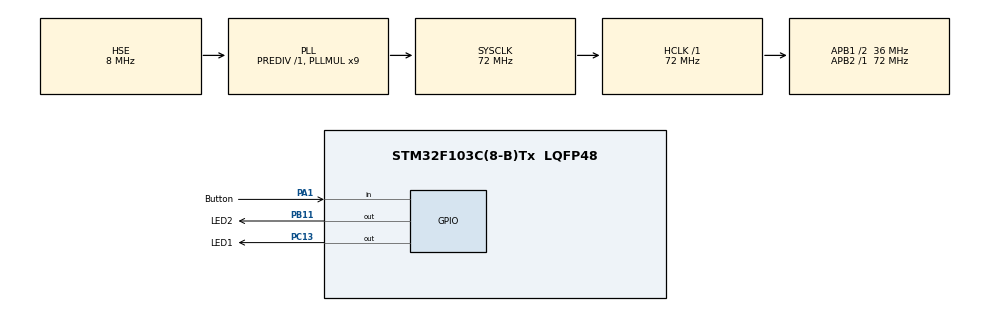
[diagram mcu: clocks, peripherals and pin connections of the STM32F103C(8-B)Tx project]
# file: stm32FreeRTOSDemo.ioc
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FREERTOS.Tasks01=task1,0,128,task1EntryFunction,Default,NULL,Dynamic,NULL,NULL;task2,-3,128,task2EntryFunction,Default,NULL,Dynamic,NULL,NULL
FREERTOS.Timers01=myTimer01,Callback01,osTimerOnce,Default,NULL,Dynamic,NULL
FREERTOS.configTIMER_TASK_PRIORITY=3
FREERTOS.configTOTAL_HEAP_SIZE=8096
FREERTOS.configUSE_TIMERS=1
Mcu.Family=STM32F1
Mcu.Name=STM32F103C(8-B)Tx
Mcu.Package=LQFP48
NVIC.PriorityGroup=NVIC_PRIORITYGROUP_4
NVIC.TIM1_UP_IRQn=true\:0\:0\:false\:false\:true\:false\:false\:true
NVIC.TimeBase=TIM1_UP_IRQn
NVIC.TimeBaseIP=TIM1
PA1.GPIO_Label=Button
PA1.Signal=GPIO_Input
PB11.GPIO_Label=LED2
PB11.Signal=GPIO_Output
PC13-TAMPER-RTC.GPIO_Label=LED1
PC13-TAMPER-RTC.Signal=GPIO_Output
PC14-OSC32_IN.Mode=LSE-External-Oscillator
PC14-OSC32_IN.Signal=RCC_OSC32_IN
PC15-OSC32_OUT.Mode=LSE-External-Oscillator
PC15-OSC32_OUT.Signal=RCC_OSC32_OUT
PD0-OSC_IN.Mode=HSE-External-Oscillator
PD0-OSC_IN.Signal=RCC_OSC_IN
PD1-OSC_OUT.Mode=HSE-External-Oscillator
PD1-OSC_OUT.Signal=RCC_OSC_OUT
ProjectManager.HeapSize=0x200
ProjectManager.StackSize=0x400
ProjectManager.TargetToolchain=Makefile
RCC.AHBFreq_Value=72000000
RCC.APB1CLKDivider=RCC_HCLK_DIV2
RCC.APB1Freq_Value=36000000
RCC.APB1TimFreq_Value=72000000
RCC.APB2Freq_Value=72000000
RCC.APB2TimFreq_Value=72000000
RCC.HCLKFreq_Value=72000000
RCC.PLLMUL=RCC_PLL_MUL9
RCC.PLLSourceVirtual=RCC_PLLSOURCE_HSE
RCC.SYSCLKFreq_VALUE=72000000
RCC.SYSCLKSource=RCC_SYSCLKSOURCE_PLLCLK
RCC.USBFreq_Value=72000000
VP_FREERTOS_VS_CMSIS_V1.Mode=CMSIS_V1
VP_SYS_VS_ND.Mode=No_Debug
VP_SYS_VS_tim1.Mode=TIM1
board=custom

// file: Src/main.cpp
/* USER CODE BEGIN Header */
/**
  ******************************************************************************
  * @file           : main.c
  * @brief          : Main program body
  ******************************************************************************
  * @attention
  *
  * <h2><center>&copy; Copyright (c) 2019 STMicroelectronics.
  * All rights reserved.</center></h2>
  *
  * This software component is licensed by ST under Ultimate Liberty license
  * SLA0044, the "License"; You may not use this file except in compliance with
  * the License. You may obtain a copy of the License at:
  *                             www.st.com/SLA0044
  *
  ******************************************************************************
  */
/* USER CODE END Header */

#include "main.h"
#include "cmsis_os.h"

osThreadId task1Handle;
osThreadId task2Handle;
osTimerId myTimer01Handle;
/* USER CODE BEGIN PV */
int timerFlag = 1;
/* USER CODE END PV */

void SystemClock_Config(void);
static void MX_GPIO_Init(void);
void task1EntryFunction(void const * argument);
void task2EntryFunction(void const * argument);
void Callback01(void const * argument);

int main(void)
{

  /* MCU Configuration--------------------------------------------------------*/

  /* Reset of all peripherals, Initializes the Flash interface and the Systick. */
  HAL_Init();

  /* Configure the system clock */
  SystemClock_Config();

  /* Initialize all configured peripherals */
  MX_GPIO_Init();

  /* Create the timer(s) */
  /* definition and creation of myTimer01 */
  osTimerDef(myTimer01, Callback01);
  myTimer01Handle = osTimerCreate(osTimer(myTimer01), osTimerOnce, NULL);

  /* Create the thread(s) */
  /* definition and creation of task1 */
  osThreadDef(task1, task1EntryFunction, osPriorityNormal, 0, 128);
  task1Handle = osThreadCreate(osThread(task1), NULL);

  /* definition and creation of task2 */
  osThreadDef(task2, task2EntryFunction, osPriorityNormal, 0, 128);
  task2Handle = osThreadCreate(osThread(task2), NULL);

  /* Start scheduler */
  osKernelStart();

  /* We should never get here as control is now taken by the scheduler */

  /* Infinite loop */
  while (1)
  {

  }
}

void SystemClock_Config(void)
{
  RCC_OscInitTypeDef RCC_OscInitStruct = {0};
  RCC_ClkInitTypeDef RCC_ClkInitStruct = {0};

  /** Initializes the CPU, AHB and APB busses clocks
  */
  RCC_OscInitStruct.OscillatorType = RCC_OSCILLATORTYPE_HSE;
  RCC_OscInitStruct.HSEState = RCC_HSE_ON;
  RCC_OscInitStruct.HSEPredivValue = RCC_HSE_PREDIV_DIV1;
  RCC_OscInitStruct.HSIState = RCC_HSI_ON;
  RCC_OscInitStruct.PLL.PLLState = RCC_PLL_ON;
  RCC_OscInitStruct.PLL.PLLSource = RCC_PLLSOURCE_HSE;
  RCC_OscInitStruct.PLL.PLLMUL = RCC_PLL_MUL9;
  if (HAL_RCC_OscConfig(&RCC_OscInitStruct) != HAL_OK)
  {
    Error_Handler();
  }
  /** Initializes the CPU, AHB and APB busses clocks
  */
  RCC_ClkInitStruct.ClockType = RCC_CLOCKTYPE_HCLK|RCC_CLOCKTYPE_SYSCLK
                              |RCC_CLOCKTYPE_PCLK1|RCC_CLOCKTYPE_PCLK2;
  RCC_ClkInitStruct.SYSCLKSource = RCC_SYSCLKSOURCE_PLLCLK;
  RCC_ClkInitStruct.AHBCLKDivider = RCC_SYSCLK_DIV1;
  RCC_ClkInitStruct.APB1CLKDivider = RCC_HCLK_DIV2;
  RCC_ClkInitStruct.APB2CLKDivider = RCC_HCLK_DIV1;

  if (HAL_RCC_ClockConfig(&RCC_ClkInitStruct, FLASH_LATENCY_2) != HAL_OK)
  {
    Error_Handler();
  }
}

static void MX_GPIO_Init(void)
{
  GPIO_InitTypeDef GPIO_InitStruct = {0};

  /* GPIO Ports Clock Enable */
  __HAL_RCC_GPIOC_CLK_ENABLE();
  __HAL_RCC_GPIOD_CLK_ENABLE();
  __HAL_RCC_GPIOB_CLK_ENABLE();
  __HAL_RCC_GPIOA_CLK_ENABLE();

  /*Configure GPIO pin Output Level */
  HAL_GPIO_WritePin(GPIOB, LED1_Pin|LED2_Pin, GPIO_PIN_RESET);

  /*Configure GPIO pin : Button_Pin */
  GPIO_InitStruct.Pin = Button_Pin;
  GPIO_InitStruct.Mode = GPIO_MODE_INPUT;
  GPIO_InitStruct.Pull = GPIO_PULLUP;
  HAL_GPIO_Init(Button_GPIO_Port, &GPIO_InitStruct);

  /*Configure GPIO pins : LED1_Pin LED2_Pin */
  GPIO_InitStruct.Pin = LED1_Pin;
  GPIO_InitStruct.Mode = GPIO_MODE_OUTPUT_PP;
  GPIO_InitStruct.Pull = GPIO_NOPULL;
  GPIO_InitStruct.Speed = GPIO_SPEED_FREQ_LOW;
  HAL_GPIO_Init(LED1_GPIO_Port, &GPIO_InitStruct);

  GPIO_InitStruct.Pin = LED2_Pin;
  GPIO_InitStruct.Mode = GPIO_MODE_OUTPUT_PP;
  GPIO_InitStruct.Pull = GPIO_NOPULL;
  GPIO_InitStruct.Speed = GPIO_SPEED_FREQ_LOW;
  HAL_GPIO_Init(LED2_GPIO_Port, &GPIO_InitStruct);
}

void task1EntryFunction(void const * argument)
{

  /* USER CODE BEGIN 5 */
  /* Infinite loop */
  for(;;)
  {
   	if(timerFlag == 1)
   	{
   		timerFlag = 0;
   		HAL_GPIO_TogglePin(LED1_GPIO_Port,LED1_Pin);
   		osTimerStart(myTimer01Handle,1000);
   	}
   	//code
  }
  /* USER CODE END 5 */
}

void task2EntryFunction(void const * argument)
{
  /* USER CODE BEGIN task2EntryFunction */
  /* Infinite loop */
  for(;;)
  {
    if( GPIO_PIN_RESET == HAL_GPIO_ReadPin(Button_GPIO_Port,Button_Pin))
    {
    	while( GPIO_PIN_RESET == HAL_GPIO_ReadPin(Button_GPIO_Port,Button_Pin));
    	osDelay(400);
    	HAL_GPIO_TogglePin(LED2_GPIO_Port,LED2_Pin);
    }
  }
  /* USER CODE END task2EntryFunction */
}

/* Callback01 function */
void Callback01(void const * argument)
{
  /* USER CODE BEGIN Callback01 */
	timerFlag = 1;
  /* USER CODE END Callback01 */
}

void HAL_TIM_PeriodElapsedCallback(TIM_HandleTypeDef *htim)
{
  if (htim->Instance == TIM1) {
    HAL_IncTick();
  }
}

void Error_Handler(void)
{
}

/************************ (C) COPYRIGHT STMicroelectronics *****END OF FILE****/
